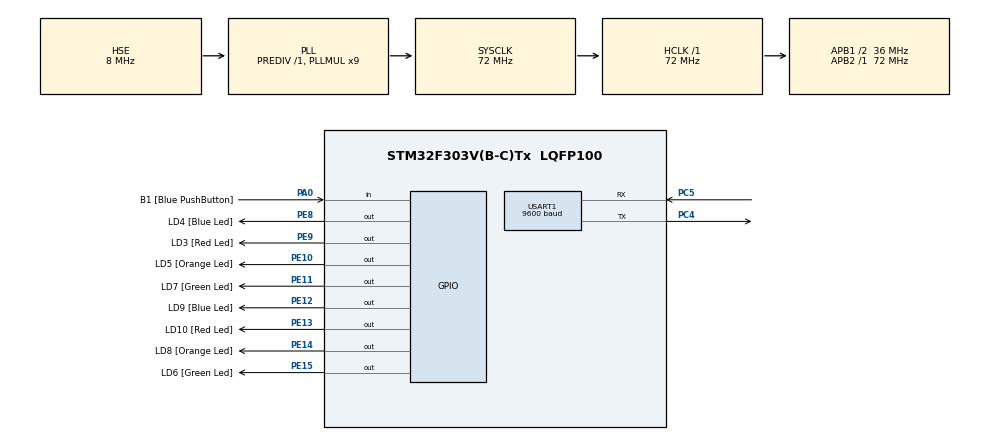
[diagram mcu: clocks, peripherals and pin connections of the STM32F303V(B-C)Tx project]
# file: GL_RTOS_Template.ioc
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Dma.Request0=USART1_TX
Dma.USART1_TX.0.Direction=DMA_MEMORY_TO_PERIPH
Dma.USART1_TX.0.Instance=DMA1_Channel4
Dma.USART1_TX.0.MemDataAlignment=DMA_MDATAALIGN_BYTE
Dma.USART1_TX.0.MemInc=DMA_MINC_ENABLE
Dma.USART1_TX.0.Mode=DMA_NORMAL
Dma.USART1_TX.0.PeriphDataAlignment=DMA_PDATAALIGN_BYTE
Dma.USART1_TX.0.PeriphInc=DMA_PINC_DISABLE
Dma.USART1_TX.0.Priority=DMA_PRIORITY_LOW
FREERTOS.Tasks01=defaultTask,24,128,StartDefaultTask,Default,NULL,Dynamic,NULL,NULL
Mcu.Family=STM32F3
Mcu.Name=STM32F303V(B-C)Tx
Mcu.Package=LQFP100
NVIC.DMA1_Channel4_IRQn=true\:5\:0\:false\:false\:true\:true\:false\:true
NVIC.PriorityGroup=NVIC_PRIORITYGROUP_4
NVIC.TIM7_IRQn=true\:0\:0\:false\:false\:true\:false\:false\:true
NVIC.TimeBase=TIM7_IRQn
NVIC.TimeBaseIP=TIM7
NVIC.USART1_IRQn=true\:5\:0\:false\:false\:true\:true\:true\:true
PA0.GPIO_Label=B1 [Blue PushButton]
PA0.Signal=GPIO_Input
PC4.Mode=Asynchronous
PC4.Signal=USART1_TX
PC5.Mode=Asynchronous
PC5.Signal=USART1_RX
PE10.GPIO_Label=LD5 [Orange Led]
PE10.Signal=GPIO_Output
PE11.GPIO_Label=LD7 [Green Led]
PE11.Signal=GPIO_Output
PE12.GPIO_Label=LD9 [Blue Led]
PE12.Signal=GPIO_Output
PE13.GPIO_Label=LD10 [Red Led]
PE13.Signal=GPIO_Output
PE14.GPIO_Label=LD8 [Orange Led]
PE14.Signal=GPIO_Output
PE15.GPIO_Label=LD6 [Green Led]
PE15.Signal=GPIO_Output
PE8.GPIO_Label=LD4 [Blue Led]
PE8.Signal=GPIO_Output
PE9.GPIO_Label=LD3 [Red Led]
PE9.Signal=GPIO_Output
PF0-OSC_IN.Mode=HSE-External-Oscillator
PF0-OSC_IN.Signal=RCC_OSC_IN
PF1-OSC_OUT.Mode=HSE-External-Oscillator
PF1-OSC_OUT.Signal=RCC_OSC_OUT
ProjectManager.HeapSize=0x200
ProjectManager.StackSize=0x400
ProjectManager.TargetToolchain=MDK-ARM V5.27
RCC.AHBFreq_Value=72000000
RCC.APB1CLKDivider=RCC_HCLK_DIV2
RCC.APB1Freq_Value=36000000
RCC.APB1TimFreq_Value=72000000
RCC.APB2Freq_Value=72000000
RCC.APB2TimFreq_Value=72000000
RCC.CortexFreq_Value=72000000
RCC.HCLKFreq_Value=72000000
RCC.HSE_VALUE=8000000
RCC.HSI_VALUE=8000000
RCC.LSE_VALUE=32768
RCC.PLLMUL=RCC_PLL_MUL9
RCC.PLLSourceVirtual=RCC_PLLSOURCE_HSE
RCC.SYSCLKFreq_VALUE=72000000
RCC.SYSCLKSourceVirtual=RCC_SYSCLKSOURCE_PLLCLK
RCC.USBFreq_Value=72000000
USART1.BaudRate=9600
USART1.VirtualMode-Asynchronous=VM_ASYNC
VP_FREERTOS_VS_CMSIS_V2.Mode=CMSIS_V2
VP_SYS_VS_tim7.Mode=TIM7
board=STM32F3DISCOVERY

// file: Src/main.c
/* USER CODE BEGIN Header */
/**
  ******************************************************************************
  * @file           : main.c
  * @brief          : Main program body
  ******************************************************************************
  * @attention
  *
  * <h2><center>&copy; Copyright (c) 2020 STMicroelectronics.
  * All rights reserved.</center></h2>
  *
  * This software component is licensed by ST under BSD 3-Clause license,
  * the "License"; You may not use this file except in compliance with the
  * License. You may obtain a copy of the License at:
  *                        opensource.org/licenses/BSD-3-Clause
  *
  ******************************************************************************
  */
/* USER CODE END Header */

#include "main.h"
#include "cmsis_os.h"

/* USER CODE BEGIN PD */
uint8_t buffTx[256]; // created buff to transfer data through DMA to UART1
uint16_t len, i;
/* USER CODE END PD */

UART_HandleTypeDef huart1;// UART1 pins connected to USB ST-LINK (PC5 & PC4)
					      // [for more detail please look through Schematic that atached to project]
DMA_HandleTypeDef hdma_usart1_tx;

osThreadId_t defaultTaskHandle;

void SystemClock_Config(void);
static void MX_GPIO_Init(void);
static void MX_DMA_Init(void);
static void MX_USART1_UART_Init(void);
void StartDefaultTask(void *argument);

int main(void)
{

  /* MCU Configuration--------------------------------------------------------*/

  /* Reset of all peripherals, Initializes the Flash interface and the Systick. */
  HAL_Init();

  /* Configure the system clock */
  SystemClock_Config();

  /* Initialize all configured peripherals */
  MX_GPIO_Init();
  MX_DMA_Init();
  MX_USART1_UART_Init();

  osKernelInitialize();

  /* Create the thread(s) */
  /* definition and creation of defaultTask */
  const osThreadAttr_t defaultTask_attributes = {
    .name = "defaultTask",
    .priority = (osPriority_t) osPriorityNormal,
    .stack_size = 128
  };
  defaultTaskHandle = osThreadNew(StartDefaultTask, NULL, &defaultTask_attributes);

  /* Start scheduler */
  osKernelStart();

  /* We should never get here as control is now taken by the scheduler */

  /* Infinite loop */
  while (1)
  {

  }
}

void SystemClock_Config(void)
{
  RCC_OscInitTypeDef RCC_OscInitStruct = {0};
  RCC_ClkInitTypeDef RCC_ClkInitStruct = {0};
  RCC_PeriphCLKInitTypeDef PeriphClkInit = {0};

  /** Initializes the CPU, AHB and APB busses clocks
  */
  RCC_OscInitStruct.OscillatorType = RCC_OSCILLATORTYPE_HSE;
  RCC_OscInitStruct.HSEState = RCC_HSE_ON;
  RCC_OscInitStruct.HSEPredivValue = RCC_HSE_PREDIV_DIV1;
  RCC_OscInitStruct.HSIState = RCC_HSI_ON;
  RCC_OscInitStruct.PLL.PLLState = RCC_PLL_ON;
  RCC_OscInitStruct.PLL.PLLSource = RCC_PLLSOURCE_HSE;
  RCC_OscInitStruct.PLL.PLLMUL = RCC_PLL_MUL9;
  if (HAL_RCC_OscConfig(&RCC_OscInitStruct) != HAL_OK)
  {
    Error_Handler();
  }
  /** Initializes the CPU, AHB and APB busses clocks
  */
  RCC_ClkInitStruct.ClockType = RCC_CLOCKTYPE_HCLK|RCC_CLOCKTYPE_SYSCLK
                              |RCC_CLOCKTYPE_PCLK1|RCC_CLOCKTYPE_PCLK2;
  RCC_ClkInitStruct.SYSCLKSource = RCC_SYSCLKSOURCE_PLLCLK;
  RCC_ClkInitStruct.AHBCLKDivider = RCC_SYSCLK_DIV1;
  RCC_ClkInitStruct.APB1CLKDivider = RCC_HCLK_DIV2;
  RCC_ClkInitStruct.APB2CLKDivider = RCC_HCLK_DIV1;

  if (HAL_RCC_ClockConfig(&RCC_ClkInitStruct, FLASH_LATENCY_2) != HAL_OK)
  {
    Error_Handler();
  }
  PeriphClkInit.PeriphClockSelection = RCC_PERIPHCLK_USART1;
  PeriphClkInit.Usart1ClockSelection = RCC_USART1CLKSOURCE_PCLK2;
  if (HAL_RCCEx_PeriphCLKConfig(&PeriphClkInit) != HAL_OK)
  {
    Error_Handler();
  }
}

static void MX_USART1_UART_Init(void)
{

  huart1.Instance = USART1;
  huart1.Init.BaudRate = 9600;
  huart1.Init.WordLength = UART_WORDLENGTH_8B;
  huart1.Init.StopBits = UART_STOPBITS_1;
  huart1.Init.Parity = UART_PARITY_NONE;
  huart1.Init.Mode = UART_MODE_TX_RX;
  huart1.Init.HwFlowCtl = UART_HWCONTROL_NONE;
  huart1.Init.OverSampling = UART_OVERSAMPLING_16;
  huart1.Init.OneBitSampling = UART_ONE_BIT_SAMPLE_DISABLE;
  huart1.AdvancedInit.AdvFeatureInit = UART_ADVFEATURE_NO_INIT;
  if (HAL_UART_Init(&huart1) != HAL_OK)
  {
    Error_Handler();
  }

}

static void MX_DMA_Init(void)
{

  /* DMA controller clock enable */
  __HAL_RCC_DMA1_CLK_ENABLE();

  /* DMA interrupt init */
  /* DMA1_Channel4_IRQn interrupt configuration */
  HAL_NVIC_SetPriority(DMA1_Channel4_IRQn, 5, 0);
  HAL_NVIC_EnableIRQ(DMA1_Channel4_IRQn);

}

static void MX_GPIO_Init(void)
{
  GPIO_InitTypeDef GPIO_InitStruct = {0};

  /* GPIO Ports Clock Enable */
  __HAL_RCC_GPIOF_CLK_ENABLE();
  __HAL_RCC_GPIOA_CLK_ENABLE();
  __HAL_RCC_GPIOC_CLK_ENABLE();
  __HAL_RCC_GPIOE_CLK_ENABLE();

  /*Configure GPIO pin Output Level */
  HAL_GPIO_WritePin(GPIOE, LD4_Pin|LD3_Pin|LD5_Pin|LD7_Pin
                          |LD9_Pin|LD10_Pin|LD8_Pin|LD6_Pin, GPIO_PIN_RESET);

  /*Configure GPIO pin : B1_Pin */
  GPIO_InitStruct.Pin = B1_Pin;
  GPIO_InitStruct.Mode = GPIO_MODE_INPUT;
  GPIO_InitStruct.Pull = GPIO_NOPULL;
  HAL_GPIO_Init(B1_GPIO_Port, &GPIO_InitStruct);

  /*Configure GPIO pins : LD4_Pin LD3_Pin LD5_Pin LD7_Pin
                           LD9_Pin LD10_Pin LD8_Pin LD6_Pin */
  GPIO_InitStruct.Pin = LD4_Pin|LD3_Pin|LD5_Pin|LD7_Pin
                          |LD9_Pin|LD10_Pin|LD8_Pin|LD6_Pin;
  GPIO_InitStruct.Mode = GPIO_MODE_OUTPUT_PP;
  GPIO_InitStruct.Pull = GPIO_NOPULL;
  GPIO_InitStruct.Speed = GPIO_SPEED_FREQ_LOW;
  HAL_GPIO_Init(GPIOE, &GPIO_InitStruct);

}

void StartDefaultTask(void *argument)
{
  /* USER CODE BEGIN 5 */

  /* Infinite loop */
  for(;;)
  {
	  if (HAL_GPIO_ReadPin(GPIOA, GPIO_PIN_0)!=GPIO_PIN_RESET)
	{
		for (i=0; i<256; i++) buffTx[i] = i;
		len = sizeof(buffTx);
		HAL_GPIO_TogglePin(GPIOE, GPIO_PIN_8);
		HAL_UART_Transmit_DMA(&huart1, buffTx, len);
	}
    osDelay(100);
  }
  /* USER CODE END 5 */
}

void HAL_TIM_PeriodElapsedCallback(TIM_HandleTypeDef *htim)
{
  if (htim->Instance == TIM7) {
    HAL_IncTick();
  }
}

void Error_Handler(void)
{
}

/************************ (C) COPYRIGHT STMicroelectronics *****END OF FILE****/
